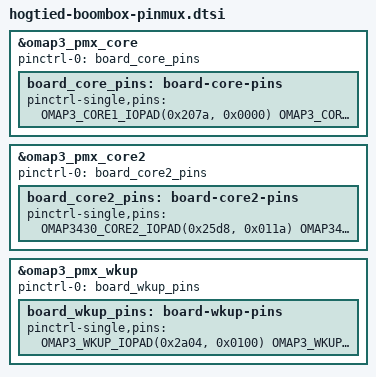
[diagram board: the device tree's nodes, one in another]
// SPDX-License-Identifier: GPL-2.0-only
/*
 * GENERATED by tools/pinmux/gen_pinmux.py - do not edit by hand.
 *
 * Board pad configuration = the stock IPL pad table (155 halfword writes,
 * IPL body offset 0x4240, written by 0x40200CC4). HogTiedOS boots directly
 * from the IPL, so these hogs re-apply the state the kernel already has.
 * Names are AM35xx (SPRUGR0C) compatible labels, comments only; they are
 * not proof of DRA526 ball or net names.
 */
#include <dt-bindings/pinctrl/omap.h>

&omap3_pmx_core {
	status = "okay";
	pinctrl-names = "default";
	pinctrl-0 = <&board_core_pins>;

	board_core_pins: board-core-pins {
		pinctrl-single,pins = <
			OMAP3_CORE1_IOPAD(0x207a, 0x0000)	/* gpmc_a1: mode 0, input off, no pull */
			OMAP3_CORE1_IOPAD(0x207c, 0x0000)	/* gpmc_a2: mode 0, input off, no pull */
			OMAP3_CORE1_IOPAD(0x207e, 0x0000)	/* gpmc_a3: mode 0, input off, no pull */
			OMAP3_CORE1_IOPAD(0x2080, 0x0000)	/* gpmc_a4: mode 0, input off, no pull */
			OMAP3_CORE1_IOPAD(0x2082, 0x0000)	/* gpmc_a5: mode 0, input off, no pull */
			OMAP3_CORE1_IOPAD(0x2084, 0x0000)	/* gpmc_a6: mode 0, input off, no pull */
			OMAP3_CORE1_IOPAD(0x2086, 0x0000)	/* gpmc_a7: mode 0, input off, no pull */
			OMAP3_CORE1_IOPAD(0x2088, 0x0000)	/* gpmc_a8: mode 0, input off, no pull */
			OMAP3_CORE1_IOPAD(0x208a, 0x0000)	/* gpmc_a9: mode 0, input off, no pull */
			OMAP3_CORE1_IOPAD(0x208c, 0x0000)	/* gpmc_a10: mode 0, input off, no pull */
			OMAP3_CORE1_IOPAD(0x208e, 0x0100)	/* gpmc_d0: mode 0, input, no pull */
			OMAP3_CORE1_IOPAD(0x2090, 0x0100)	/* gpmc_d1: mode 0, input, no pull */
			OMAP3_CORE1_IOPAD(0x2092, 0x0100)	/* gpmc_d2: mode 0, input, no pull */
			OMAP3_CORE1_IOPAD(0x2094, 0x0100)	/* gpmc_d3: mode 0, input, no pull */
			OMAP3_CORE1_IOPAD(0x2096, 0x0100)	/* gpmc_d4: mode 0, input, no pull */
			OMAP3_CORE1_IOPAD(0x2098, 0x0100)	/* gpmc_d5: mode 0, input, no pull */
			OMAP3_CORE1_IOPAD(0x209a, 0x0100)	/* gpmc_d6: mode 0, input, no pull */
			OMAP3_CORE1_IOPAD(0x209c, 0x0100)	/* gpmc_d7: mode 0, input, no pull */
			OMAP3_CORE1_IOPAD(0x209e, 0x0100)	/* gpmc_d8: mode 0, input, no pull */
			OMAP3_CORE1_IOPAD(0x20a0, 0x0100)	/* gpmc_d9: mode 0, input, no pull */
			OMAP3_CORE1_IOPAD(0x20a2, 0x0100)	/* gpmc_d10: mode 0, input, no pull */
			OMAP3_CORE1_IOPAD(0x20a4, 0x0100)	/* gpmc_d11: mode 0, input, no pull */
			OMAP3_CORE1_IOPAD(0x20a6, 0x0100)	/* gpmc_d12: mode 0, input, no pull */
			OMAP3_CORE1_IOPAD(0x20a8, 0x0100)	/* gpmc_d13: mode 0, input, no pull */
			OMAP3_CORE1_IOPAD(0x20aa, 0x0100)	/* gpmc_d14: mode 0, input, no pull */
			OMAP3_CORE1_IOPAD(0x20ac, 0x0100)	/* gpmc_d15: mode 0, input, no pull */
			OMAP3_CORE1_IOPAD(0x20ae, 0x0018)	/* gpmc_ncs0: mode 0, input off, pull-up */
			OMAP3_CORE1_IOPAD(0x20b4, 0x0018)	/* gpmc_ncs3: mode 0, input off, pull-up */
			OMAP3_CORE1_IOPAD(0x20b8, 0x0104)	/* gpmc_ncs5 -> gpio_56: mode 4, input, no pull */
			OMAP3_CORE1_IOPAD(0x20c0, 0x0000)	/* gpmc_nadv_ale: mode 0, input off, no pull */
			OMAP3_CORE1_IOPAD(0x20c2, 0x0000)	/* gpmc_noe: mode 0, input off, no pull */
			OMAP3_CORE1_IOPAD(0x20c4, 0x0000)	/* gpmc_nwe: mode 0, input off, no pull */
			OMAP3_CORE1_IOPAD(0x20c6, 0x0018)	/* gpmc_nbe0_cle: mode 0, input off, pull-up */
			OMAP3_CORE1_IOPAD(0x20ca, 0x0100)	/* gpmc_nwp: mode 0, input, no pull */
			OMAP3_CORE1_IOPAD(0x20d0, 0x0004)	/* gpmc_wait2 -> gpio_64: mode 4, input off, no pull */
			OMAP3_CORE1_IOPAD(0x20d4, 0x0000)	/* dss_pclk: mode 0, input off, no pull */
			OMAP3_CORE1_IOPAD(0x20d6, 0x0000)	/* dss_hsync: mode 0, input off, no pull */
			OMAP3_CORE1_IOPAD(0x20d8, 0x0000)	/* dss_vsync: mode 0, input off, no pull */
			OMAP3_CORE1_IOPAD(0x20da, 0x0000)	/* dss_acbias: mode 0, input off, no pull */
			OMAP3_CORE1_IOPAD(0x20dc, 0x0000)	/* dss_data0: mode 0, input off, no pull */
			OMAP3_CORE1_IOPAD(0x20de, 0x0000)	/* dss_data1: mode 0, input off, no pull */
			OMAP3_CORE1_IOPAD(0x20e0, 0x0000)	/* dss_data2: mode 0, input off, no pull */
			OMAP3_CORE1_IOPAD(0x20e2, 0x0000)	/* dss_data3: mode 0, input off, no pull */
			OMAP3_CORE1_IOPAD(0x20e4, 0x0000)	/* dss_data4: mode 0, input off, no pull */
			OMAP3_CORE1_IOPAD(0x20e6, 0x0000)	/* dss_data5: mode 0, input off, no pull */
			OMAP3_CORE1_IOPAD(0x20e8, 0x0000)	/* dss_data6: mode 0, input off, no pull */
			OMAP3_CORE1_IOPAD(0x20ea, 0x0000)	/* dss_data7: mode 0, input off, no pull */
			OMAP3_CORE1_IOPAD(0x20ec, 0x0000)	/* dss_data8: mode 0, input off, no pull */
			OMAP3_CORE1_IOPAD(0x20ee, 0x0000)	/* dss_data9: mode 0, input off, no pull */
			OMAP3_CORE1_IOPAD(0x20f0, 0x0000)	/* dss_data10: mode 0, input off, no pull */
			OMAP3_CORE1_IOPAD(0x20f2, 0x0000)	/* dss_data11: mode 0, input off, no pull */
			OMAP3_CORE1_IOPAD(0x20f4, 0x0000)	/* dss_data12: mode 0, input off, no pull */
			OMAP3_CORE1_IOPAD(0x20f6, 0x0000)	/* dss_data13: mode 0, input off, no pull */
			OMAP3_CORE1_IOPAD(0x20f8, 0x0000)	/* dss_data14: mode 0, input off, no pull */
			OMAP3_CORE1_IOPAD(0x20fa, 0x0000)	/* dss_data15: mode 0, input off, no pull */
			OMAP3_CORE1_IOPAD(0x213c, 0x0100)	/* mcbsp2_fsx: mode 0, input, no pull */
			OMAP3_CORE1_IOPAD(0x213e, 0x0100)	/* mcbsp2_clkx: mode 0, input, no pull */
			OMAP3_CORE1_IOPAD(0x2140, 0x0100)	/* mcbsp2_dr: mode 0, input, no pull */
			OMAP3_CORE1_IOPAD(0x2142, 0x0000)	/* mcbsp2_dx: mode 0, input off, no pull */
			OMAP3_CORE1_IOPAD(0x2144, 0x0118)	/* mmc1_clk: mode 0, input, pull-up */
			OMAP3_CORE1_IOPAD(0x2146, 0x0118)	/* mmc1_cmd: mode 0, input, pull-up */
			OMAP3_CORE1_IOPAD(0x2148, 0x0118)	/* mmc1_dat0: mode 0, input, pull-up */
			OMAP3_CORE1_IOPAD(0x214a, 0x0118)	/* mmc1_dat1: mode 0, input, pull-up */
			OMAP3_CORE1_IOPAD(0x214c, 0x0118)	/* mmc1_dat2: mode 0, input, pull-up */
			OMAP3_CORE1_IOPAD(0x214e, 0x0118)	/* mmc1_dat3: mode 0, input, pull-up */
			OMAP3_CORE1_IOPAD(0x2150, 0x0118)	/* mmc1_dat4: mode 0, input, pull-up */
			OMAP3_CORE1_IOPAD(0x2152, 0x0118)	/* mmc1_dat5: mode 0, input, pull-up */
			OMAP3_CORE1_IOPAD(0x2154, 0x0118)	/* mmc1_dat6: mode 0, input, pull-up */
			OMAP3_CORE1_IOPAD(0x2156, 0x0118)	/* mmc1_dat7: mode 0, input, pull-up */
			OMAP3_CORE1_IOPAD(0x2158, 0x0118)	/* mmc2_clk: mode 0, input, pull-up */
			OMAP3_CORE1_IOPAD(0x215a, 0x0118)	/* mmc2_cmd: mode 0, input, pull-up */
			OMAP3_CORE1_IOPAD(0x215c, 0x0118)	/* mmc2_dat0: mode 0, input, pull-up */
			OMAP3_CORE1_IOPAD(0x215e, 0x0118)	/* mmc2_dat1: mode 0, input, pull-up */
			OMAP3_CORE1_IOPAD(0x2160, 0x0118)	/* mmc2_dat2: mode 0, input, pull-up */
			OMAP3_CORE1_IOPAD(0x2162, 0x0118)	/* mmc2_dat3: mode 0, input, pull-up */
			OMAP3_CORE1_IOPAD(0x2164, 0x0104)	/* mmc2_dat4 -> gpio_136: mode 4, input, no pull */
			OMAP3_CORE1_IOPAD(0x2166, 0x0104)	/* mmc2_dat5 -> gpio_137: mode 4, input, no pull */
			OMAP3_CORE1_IOPAD(0x2170, 0x0000)	/* mcbsp3_clkx: mode 0, input off, no pull */
			OMAP3_CORE1_IOPAD(0x2172, 0x0000)	/* mcbsp3_fsx: mode 0, input off, no pull */
			OMAP3_CORE1_IOPAD(0x2178, 0x0000)	/* uart2_tx: mode 0, input off, no pull */
			OMAP3_CORE1_IOPAD(0x217a, 0x0100)	/* uart2_rx: mode 0, input, no pull */
			OMAP3_CORE1_IOPAD(0x217c, 0x0010)	/* uart1_tx: mode 0, input off, no pull */
			OMAP3_CORE1_IOPAD(0x217e, 0x0114)	/* uart1_rts -> gpio_149: mode 4, input, no pull */
			OMAP3_CORE1_IOPAD(0x2182, 0x0100)	/* uart1_rx: mode 0, input, no pull */
			OMAP3_CORE1_IOPAD(0x2184, 0x0100)	/* mcbsp4_clkx: mode 0, input, no pull */
			OMAP3_CORE1_IOPAD(0x2186, 0x0100)	/* mcbsp4_dr: mode 0, input, no pull */
			OMAP3_CORE1_IOPAD(0x2188, 0x0100)	/* mcbsp4_dx: mode 0, input, no pull */
			OMAP3_CORE1_IOPAD(0x218a, 0x0100)	/* mcbsp4_fsx: mode 0, input, no pull */
			OMAP3_CORE1_IOPAD(0x218c, 0x0100)	/* mcbsp1_clkr: mode 0, input, no pull */
			OMAP3_CORE1_IOPAD(0x218e, 0x0018)	/* mcbsp1_fsr: mode 0, input off, pull-up */
			OMAP3_CORE1_IOPAD(0x2190, 0x0000)	/* mcbsp1_dx: mode 0, input off, no pull */
			OMAP3_CORE1_IOPAD(0x2192, 0x0100)	/* mcbsp1_dr: mode 0, input, no pull */
			OMAP3_CORE1_IOPAD(0x2194, 0x0110)	/* mcbsp_clks: mode 0, input, no pull */
			OMAP3_CORE1_IOPAD(0x2196, 0x0100)	/* mcbsp1_fsx: mode 0, input, no pull */
			OMAP3_CORE1_IOPAD(0x2198, 0x0100)	/* mcbsp1_clkx: mode 0, input, no pull */
			OMAP3_CORE1_IOPAD(0x219e, 0x0100)	/* uart3_rx_irrx: mode 0, input, no pull */
			OMAP3_CORE1_IOPAD(0x21a0, 0x0000)	/* uart3_tx_irtx: mode 0, input off, no pull */
			OMAP3_CORE1_IOPAD(0x21ba, 0x0118)	/* i2c1_scl (inferred: pairs with i2c1_sda at 0x21bc): mode 0, input, pull-up */
			OMAP3_CORE1_IOPAD(0x21bc, 0x0118)	/* i2c1_sda: mode 0, input, pull-up */
			OMAP3_CORE1_IOPAD(0x21be, 0x0118)	/* i2c2_scl: mode 0, input, pull-up */
			OMAP3_CORE1_IOPAD(0x21c0, 0x0118)	/* i2c2_sda: mode 0, input, pull-up */
			OMAP3_CORE1_IOPAD(0x21c2, 0x0118)	/* i2c3_scl: mode 0, input, pull-up */
			OMAP3_CORE1_IOPAD(0x21c4, 0x0118)	/* i2c3_sda: mode 0, input, pull-up */
			OMAP3_CORE1_IOPAD(0x21c6, 0x0004)	/* hdq_sio -> gpio_170: mode 4, input off, no pull */
			OMAP3_CORE1_IOPAD(0x21d6, 0x0100)	/* mcspi2_clk: mode 0, input, no pull */
			OMAP3_CORE1_IOPAD(0x21d8, 0x0100)	/* mcspi2_simo: mode 0, input, no pull */
			OMAP3_CORE1_IOPAD(0x21da, 0x0100)	/* mcspi2_somi: mode 0, input, no pull */
			OMAP3_CORE1_IOPAD(0x21dc, 0x0108)	/* mcspi2_cs0: mode 0, input, pull-down */
			OMAP3_CORE1_IOPAD(0x21e0, 0x0114)	/* sys_nirq -> gpio_0: mode 4, input, no pull */
			OMAP3_CORE1_IOPAD(0x21e2, 0x0118)	/* sys_clkout2: mode 0, input, pull-up */
			OMAP3_CORE1_IOPAD(0x21e4, 0x0114)	/* ccdc_pclk -> gpio_94: mode 4, input, no pull */
			OMAP3_CORE1_IOPAD(0x21e6, 0x0002)	/* ccdc_field (mode 2 function not labeled): mode 2, input off, no pull */
			OMAP3_CORE1_IOPAD(0x21e8, 0x0114)	/* ccdc_hd -> gpio_96: mode 4, input, no pull */
			OMAP3_CORE1_IOPAD(0x21ea, 0x010c)	/* ccdc_vd -> gpio_97: mode 4, input, pull-down */
			OMAP3_CORE1_IOPAD(0x21ec, 0x0102)	/* ccdc_wen (mode 2 function not labeled): mode 2, input, no pull */
			OMAP3_CORE1_IOPAD(0x21ee, 0x0004)	/* ccdc_data0 -> gpio_99: mode 4, input off, no pull */
			OMAP3_CORE1_IOPAD(0x21f0, 0x0004)	/* ccdc_data1 -> gpio_100: mode 4, input off, no pull */
			OMAP3_CORE1_IOPAD(0x21f2, 0x0104)	/* ccdc_data2 -> gpio_101: mode 4, input, no pull */
			OMAP3_CORE1_IOPAD(0x21f4, 0x0104)	/* ccdc_data3 -> gpio_102: mode 4, input, no pull */
			OMAP3_CORE1_IOPAD(0x21f6, 0x0004)	/* ccdc_data4 -> gpio_103: mode 4, input off, no pull */
			OMAP3_CORE1_IOPAD(0x21f8, 0x0004)	/* ccdc_data5 -> gpio_104: mode 4, input off, no pull */
			OMAP3_CORE1_IOPAD(0x21fa, 0x0004)	/* ccdc_data6 -> gpio_105: mode 4, input off, no pull */
			OMAP3_CORE1_IOPAD(0x21fc, 0x0104)	/* ccdc_data7 -> gpio_106: mode 4, input, no pull */
			OMAP3_CORE1_IOPAD(0x21fe, 0x0004)	/* rmii_mdio_data -> gpio_107: mode 4, input off, no pull */
			OMAP3_CORE1_IOPAD(0x2200, 0x0004)	/* rmii_mdio_clk -> gpio_108: mode 4, input off, no pull */
			OMAP3_CORE1_IOPAD(0x2202, 0x0004)	/* rmii_rxd0 -> gpio_109: mode 4, input off, no pull */
			OMAP3_CORE1_IOPAD(0x2204, 0x0004)	/* rmii_rxd1 -> gpio_110: mode 4, input off, no pull */
			OMAP3_CORE1_IOPAD(0x2206, 0x0004)	/* rmii_crs_dv -> gpio_111: mode 4, input off, no pull */
			OMAP3_CORE1_IOPAD(0x220c, 0x0004)	/* rmii_txd1 -> gpio_112: mode 4, input off, no pull */
			OMAP3_CORE1_IOPAD(0x220e, 0x0004)	/* rmii_txen -> gpio_113: mode 4, input off, no pull */
			OMAP3_CORE1_IOPAD(0x2212, 0x0108)	/* usb0_drvvbus: mode 0, input, pull-down */
			OMAP3_CORE1_IOPAD(0x2214, 0x0018)	/* hecc1_txd: mode 0, input off, pull-up */
			OMAP3_CORE1_IOPAD(0x2216, 0x0118)	/* hecc1_rxd: mode 0, input, pull-up */
		>;
	};
};

&omap3_pmx_core2 {
	status = "okay";
	pinctrl-names = "default";
	pinctrl-0 = <&board_core2_pins>;

	board_core2_pins: board-core2-pins {
		pinctrl-single,pins = <
			OMAP3430_CORE2_IOPAD(0x25d8, 0x011a)	/* etk_clk (mode 2 function not labeled): mode 2, input, pull-up */
			OMAP3430_CORE2_IOPAD(0x25da, 0x011a)	/* etk_ctl (mode 2 function not labeled): mode 2, input, pull-up */
			OMAP3430_CORE2_IOPAD(0x25dc, 0x0101)	/* etk_d0 (mode 1 function not labeled): mode 1, input, no pull */
			OMAP3430_CORE2_IOPAD(0x25de, 0x0101)	/* etk_d1 (mode 1 function not labeled): mode 1, input, no pull */
			OMAP3430_CORE2_IOPAD(0x25e0, 0x0109)	/* etk_d2 (mode 1 function not labeled): mode 1, input, pull-down */
			OMAP3430_CORE2_IOPAD(0x25e2, 0x011a)	/* etk_d3 (mode 2 function not labeled): mode 2, input, pull-up */
			OMAP3430_CORE2_IOPAD(0x25e4, 0x011a)	/* etk_d4 (mode 2 function not labeled): mode 2, input, pull-up */
			OMAP3430_CORE2_IOPAD(0x25e6, 0x011a)	/* etk_d5 (mode 2 function not labeled): mode 2, input, pull-up */
			OMAP3430_CORE2_IOPAD(0x25e8, 0x011a)	/* etk_d6 (mode 2 function not labeled): mode 2, input, pull-up */
			OMAP3430_CORE2_IOPAD(0x25ea, 0x0104)	/* etk_d7 -> gpio_21: mode 4, input, no pull */
			OMAP3430_CORE2_IOPAD(0x25ec, 0x001c)	/* etk_d8 -> gpio_22: mode 4, input off, pull-up */
			OMAP3430_CORE2_IOPAD(0x25ee, 0x001c)	/* etk_d9 -> gpio_23: mode 4, input off, pull-up */
			OMAP3430_CORE2_IOPAD(0x25f0, 0x000c)	/* etk_d10 -> gpio_24: mode 4, input off, pull-down */
			OMAP3430_CORE2_IOPAD(0x25f2, 0x0101)	/* etk_d11 (mode 1 function not labeled): mode 1, input, no pull */
			OMAP3430_CORE2_IOPAD(0x25f4, 0x011c)	/* etk_d12 -> gpio_26: mode 4, input, pull-up */
			OMAP3430_CORE2_IOPAD(0x25f6, 0x011c)	/* etk_d13 -> gpio_27: mode 4, input, pull-up */
			OMAP3430_CORE2_IOPAD(0x25f8, 0x0004)	/* etk_d14 -> gpio_28: mode 4, input off, no pull */
			OMAP3430_CORE2_IOPAD(0x25fa, 0x0004)	/* etk_d15 -> gpio_29: mode 4, input off, no pull */
		>;
	};
};

&omap3_pmx_wkup {
	status = "okay";
	pinctrl-names = "default";
	pinctrl-0 = <&board_wkup_pins>;

	board_wkup_pins: board-wkup-pins {
		pinctrl-single,pins = <
			OMAP3_WKUP_IOPAD(0x2a04, 0x0100)	/* sys_32k: mode 0, input, no pull */
			OMAP3_WKUP_IOPAD(0x2a06, 0x0100)	/* sys_clkreq: mode 0, input, no pull */
			OMAP3_WKUP_IOPAD(0x2a08, 0x0014)	/* sys_nreswarm -> gpio_30: mode 4, input off, no pull */
			OMAP3_WKUP_IOPAD(0x2a1a, 0x0100)	/* sys_clkout1: mode 0, input, no pull */
		>;
	};
};
